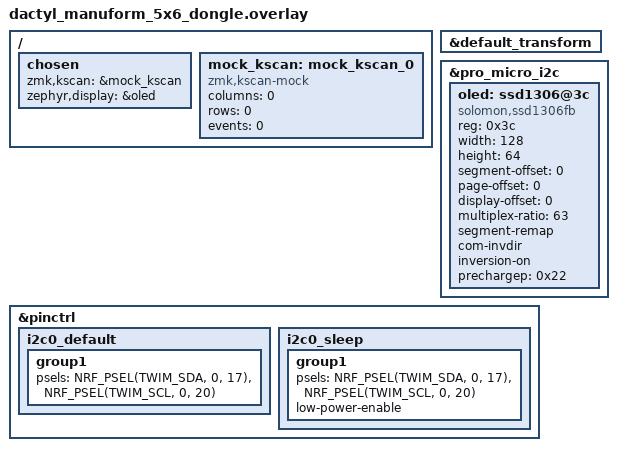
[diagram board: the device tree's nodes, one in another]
#include "dactyl_manuform_5x6.dtsi"

/ {
    chosen {
        zmk,kscan = &mock_kscan;
        zephyr,display = &oled;
    };

    mock_kscan: mock_kscan_0 {
        compatible = "zmk,kscan-mock";
        columns = <0>;
        rows = <0>;
        events = <0>;
    };
};


&default_transform { // The matrix transform for this board is 6 columns over because the left half is 6 columns wide according to the matrix.
    // rows = <0>;
};

&pro_micro_i2c {
    status = "okay";
    
    oled: ssd1306@3c {
        compatible = "solomon,ssd1306fb";
        reg = <0x3c>;
        width = <128>;
        height = <64>;
        segment-offset = <0>;
        page-offset = <0>;
        display-offset = <0>;
        multiplex-ratio = <63>;
        segment-remap;
        com-invdir;
        inversion-on;
        prechargep = <0x22>;
    };
};

&pinctrl {
    /* configuration for i2c0 device, default state */
    i2c0_default: i2c0_default {
        group1 {
            psels = <NRF_PSEL(TWIM_SDA, 0, 17)>,
                <NRF_PSEL(TWIM_SCL, 0, 20)>;
        };
    };

    i2c0_sleep: i2c0_sleep {
        group1 {
            psels = <NRF_PSEL(TWIM_SDA, 0, 17)>,
                <NRF_PSEL(TWIM_SCL, 0, 20)>;
            low-power-enable;
        };
    };
};
